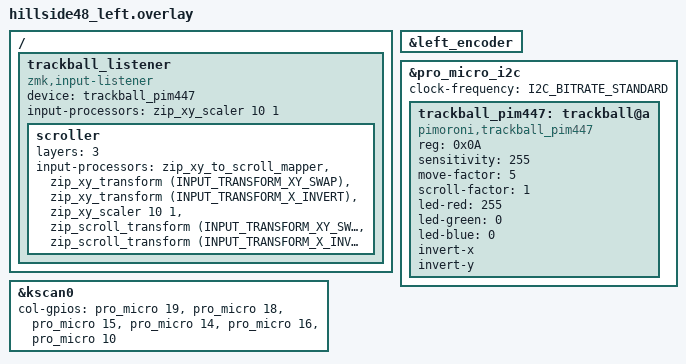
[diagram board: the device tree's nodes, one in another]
/*
 * Copyright (c) 2021 The ZMK Contributors
 *
 * SPDX-License-Identifier: MIT
 */

#include "hillside48.dtsi"
#include <input/processors.dtsi>

&kscan0 {
    col-gpios
        = <&pro_micro 19 GPIO_ACTIVE_HIGH> // col0 in the schematic
        , <&pro_micro 18 GPIO_ACTIVE_HIGH> // col1 in the schematic
        , <&pro_micro 15 GPIO_ACTIVE_HIGH> // col2 in the schematic
        , <&pro_micro 14 GPIO_ACTIVE_HIGH> // col3 in the schematic
        , <&pro_micro 16 GPIO_ACTIVE_HIGH> // col4 in the schematic
        , <&pro_micro 10 GPIO_ACTIVE_HIGH> // col5 in the schematic
        ;
};

&left_encoder {
    status = "okay";
};

&pro_micro_i2c {
    status = "okay";
    clock-frequency = <I2C_BITRATE_STANDARD>;

    trackball_pim447: trackball@a {
        compatible = "pimoroni,trackball_pim447";
        reg = <0x0A>;

        sensitivity = <255>;  /* Range: 1-255 */
        move-factor = <5>;   /* Range: 1-10, scales cursor movement speed */
        scroll-factor = <1>; /* Range: 1-10, scales scrolling speed */

        /* Optional LED color (RGB values 0-255) */
        led-red = <255>;
        led-green = <0>;
        led-blue = <0>;

        /* Optional axis inversion */
        invert-x;   /* Uncomment to invert X axis */
        invert-y;   /* Uncomment to invert Y axis */
    };
};

/ {
    trackball_listener: trackball_listener {
        compatible = "zmk,input-listener";
        device = <&trackball_pim447>;
        input-processors = <&zip_xy_scaler 10 1>;

        scroller {
            layers = <3>;  // replace with whichever layer number you want to trigger scroll
            input-processors = <
                &zip_xy_to_scroll_mapper
                &zip_xy_transform (INPUT_TRANSFORM_XY_SWAP)
                &zip_xy_transform (INPUT_TRANSFORM_X_INVERT)

                &zip_xy_scaler 10 1

                &zip_scroll_transform (INPUT_TRANSFORM_XY_SWAP)
                &zip_scroll_transform (INPUT_TRANSFORM_X_INVERT)
            >;
        };
    };
};
